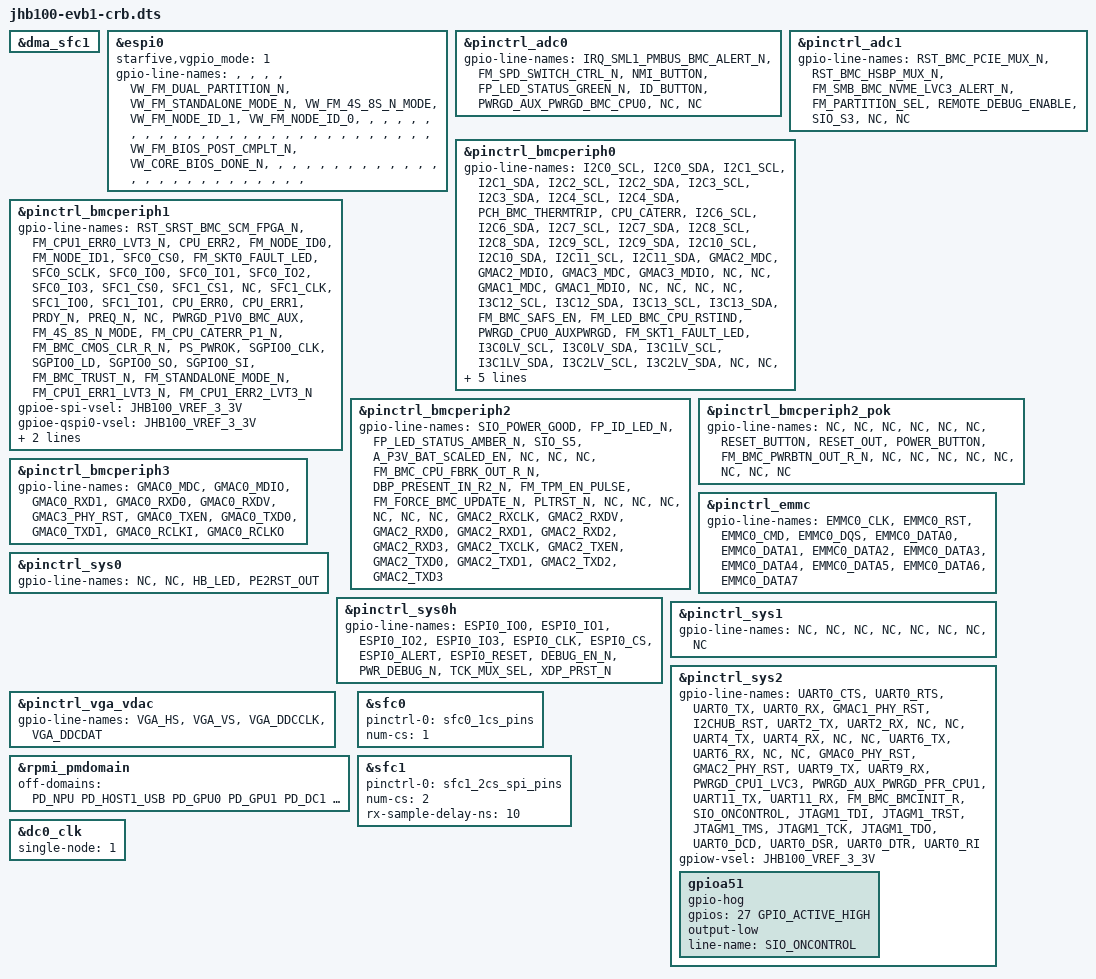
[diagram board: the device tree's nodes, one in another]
// SPDX-License-Identifier: GPL-2.0 OR MIT
/*
 * Copyright (c) 2025 StarFive Technology Co., Ltd.
 */

#include "jhb100-evb1.dtsi"
#include "jhb100-evb1-ethernet.dtsi"
#include "jhb100-evb1-sib1.dtsi"
#include "jhb100-evb1-sfc0-flash.dtsi"
#include "jhb100-evb1-sfc1-flash.dtsi"

&dma_sfc1 {
	status = "okay";
};

&espi0 {
	starfive,vgpio_mode = <1>;
	gpio-line-names  =
										/* Output pins */
		"", "", "", "",							/* VGPIO0-3 */
		"VW_FM_DUAL_PARTITION_N", "VW_FM_STANDALONE_MODE_N",		/* VGPIO4-5 */
		"VW_FM_4S_8S_N_MODE", "VW_FM_NODE_ID_1",			/* VGPIO6-7 */
		"VW_FM_NODE_ID_0", "", "", "", "", "", "", "",			/* VGPIO8-15*/
		"", "", "", "",	"", "", "", "",					/* VGPIO16-23 */
		"", "", "", "",	"", "", "", "",					/* VGPIO23-31 */
										/* Input pins */
		"", "", "", "",							/* VGPIO32-35 */
		"VW_FM_BIOS_POST_CMPLT_N", "VW_CORE_BIOS_DONE_N", "", "",	/* VGPIO36-39 */
		"", "", "", "",	"", "", "", "",					/* VGPIO40-47 */
		"", "", "", "",	"", "", "", "",					/* VGPIO48-55 */
		"", "", "", "",	"", "", "", "";					/* VGPIO56-63 */
};

&pinctrl_adc0 {
	gpio-line-names =
		"IRQ_SML1_PMBUS_BMC_ALERT_N", "FM_SPD_SWITCH_CTRL_N",		/* GPIOG0-1 */
		"NMI_BUTTON", "FP_LED_STATUS_GREEN_N",				/* GPIOG2-3 */
		"ID_BUTTON", "PWRGD_AUX_PWRGD_BMC_CPU0",			/* GPIOG4-5 */
		"NC", "NC";							/* GPIOG6-7 */
};

&pinctrl_adc1 {
	gpio-line-names =
		"RST_BMC_PCIE_MUX_N", "RST_BMC_HSBP_MUX_N",		/* GPIOH0-1 */
		"FM_SMB_BMC_NVME_LVC3_ALERT_N", "FM_PARTITION_SEL",	/* GPIOH2-3 */
		"REMOTE_DEBUG_ENABLE", "SIO_S3", "NC", "NC";		/* GPIOH4-7 */
};

&pinctrl_bmcperiph0 {
	gpio-line-names =
		"I2C0_SCL", "I2C0_SDA", "I2C1_SCL", "I2C1_SDA",			/* GPIOB0-3 */
		"I2C2_SCL", "I2C2_SDA", "I2C3_SCL", "I2C3_SDA",			/* GPIOB4-7 */
		"I2C4_SCL", "I2C4_SDA",						/* GPIOB8-9 */
		"PCH_BMC_THERMTRIP", "CPU_CATERR",				/* GPIOB10-11 */
		"I2C6_SCL", "I2C6_SDA", "I2C7_SCL", "I2C7_SDA",			/* GPIOB12-15 */
		"I2C8_SCL", "I2C8_SDA", "I2C9_SCL", "I2C9_SDA",			/* GPIOB16-19 */
		"I2C10_SCL", "I2C10_SDA", "I2C11_SCL", "I2C11_SDA",		/* GPIOB20-23 */
		"GMAC2_MDC", "GMAC2_MDIO", "GMAC3_MDC", "GMAC3_MDIO",		/* GPIOB24-27 */
		"NC", "NC", "GMAC1_MDC", "GMAC1_MDIO",				/* GPIOB28-31 */
		"NC", "NC", "NC", "NC",						/* GPIOB32-35 */
		"I3C12_SCL", "I3C12_SDA", "I3C13_SCL", "I3C13_SDA",		/* GPIOB36-39 */
		"FM_BMC_SAFS_EN", "FM_LED_BMC_CPU_RSTIND",			/* GPIOB40-41 */
		"PWRGD_CPU0_AUXPWRGD", "FM_SKT1_FAULT_LED",			/* GPIOB42-43 */
		"I3C0LV_SCL", "I3C0LV_SDA", "I3C1LV_SCL", "I3C1LV_SDA",		/* GPIOB44-47 */
		"I3C2LV_SCL", "I3C2LV_SDA", "NC", "NC",				/* GPIOB48-51 */
		"NC", "NC", "NC", "NC",						/* GPIOB52-55 */
		"NC", "NC", "NC", "NC";						/* GPIOB56-59 */

	gpioe-i3c0-vsel = <JHB100_VREF_3_3V>; /* VREF for GPIOB8-11, 32-33 */
	gpioe-i3c1-vsel = <JHB100_VREF_3_3V>; /* VREF for GPIOB12-15, 34-35 */
	gpioe-i3c2-vsel = <JHB100_VREF_3_3V>; /* VREF for GPIOB16-23 */
	gpioe-i3c4-vsel = <JHB100_VREF_3_3V>; /* VREF for GPIOB36-43 */
};

&pinctrl_bmcperiph1 {
	gpio-line-names =
		"RST_SRST_BMC_SCM_FPGA_N", "FM_CPU1_ERR0_LVT3_N",		/* GPIOC0-1 */
		"CPU_ERR2", "FM_NODE_ID0", "FM_NODE_ID1", "SFC0_CS0",		/* GPIOC2-5 */
		"FM_SKT0_FAULT_LED", "SFC0_SCLK",				/* GPIOC6-7 */
		"SFC0_IO0", "SFC0_IO1", "SFC0_IO2", "SFC0_IO3",			/* GPIOC8-11 */
		"SFC1_CS0", "SFC1_CS1", "NC", "SFC1_CLK",			/* GPIOC12-15 */
		"SFC1_IO0", "SFC1_IO1", "CPU_ERR0", "CPU_ERR1",			/* GPIOC16-19 */
		"PRDY_N", "PREQ_N", "NC", "PWRGD_P1V0_BMC_AUX",			/* GPIOC20-23 */
		"FM_4S_8S_N_MODE", "FM_CPU_CATERR_P1_N",			/* GPIOC24-25 */
		"FM_BMC_CMOS_CLR_R_N", "PS_PWROK",				/* GPIOC26-27 */
		"SGPIO0_CLK", "SGPIO0_LD", "SGPIO0_SO", "SGPIO0_SI",		/* GPIOC28-31 */
		"FM_BMC_TRUST_N", "FM_STANDALONE_MODE_N",			/* GPIOC32-33 */
		"FM_CPU1_ERR1_LVT3_N", "FM_CPU1_ERR2_LVT3_N";			/* GPIOC34-35 */

	gpioe-spi-vsel = <JHB100_VREF_3_3V>; /* VREF for GPIOC0-4 */
	gpioe-qspi0-vsel = <JHB100_VREF_3_3V>; /* VREF for GPIOC5-11 */
	gpioe-qspi1-vsel = <JHB100_VREF_3_3V>; /* VREF for GPIOC12-19 */
	gpioe-qspi2-vsel = <JHB100_VREF_3_3V>; /* VREF for GPIOC20-27 */
};

&pinctrl_bmcperiph2 {
	gpio-line-names =
		"SIO_POWER_GOOD", "FP_ID_LED_N",				/* GPIOD0-1 */
		"FP_LED_STATUS_AMBER_N", "SIO_S5",				/* GPIOD2-3 */
		"A_P3V_BAT_SCALED_EN", "NC", "NC", "NC",			/* GPIOD4-7 */
		"FM_BMC_CPU_FBRK_OUT_R_N", "DBP_PRESENT_IN_R2_N",		/* GPIOD8-9 */
		"FM_TPM_EN_PULSE", "FM_FORCE_BMC_UPDATE_N",			/* GPIOD10-11 */
		"PLTRST_N", "NC", "NC", "NC",					/* GPIOD12-15 */
		"NC", "NC", "NC", "GMAC2_RXCLK",				/* GPIOD16-19 */
		"GMAC2_RXDV", "GMAC2_RXD0", "GMAC2_RXD1", "GMAC2_RXD2",		/* GPIOD20-23 */
		"GMAC2_RXD3", "GMAC2_TXCLK", "GMAC2_TXEN", "GMAC2_TXD0",	/* GPIOD24-27 */
		"GMAC2_TXD1", "GMAC2_TXD2", "GMAC2_TXD3";			/* GPIOD28-30 */
};

&pinctrl_bmcperiph2_pok {
	gpio-line-names =
		"NC", "NC", "NC", "NC",				/* GPIOD31-34 */
		"NC", "NC", "RESET_BUTTON", "RESET_OUT",	/* GPIOD35-38 */
		"POWER_BUTTON", "FM_BMC_PWRBTN_OUT_R_N",	/* GPIOD39-40 */
		"NC", "NC", "NC", "NC",				/* GPIOD41-44 */
		"NC", "NC", "NC", "NC";				/* GPIOD45-48 */
};

&pinctrl_bmcperiph3 {
	gpio-line-names =
		"GMAC0_MDC", "GMAC0_MDIO", "GMAC0_RXD1", "GMAC0_RXD0",		/* GPIOE0-3 */
		"GMAC0_RXDV", "GMAC3_PHY_RST", "GMAC0_TXEN", "GMAC0_TXD0",	/* GPIOE4-7 */
		"GMAC0_TXD1", "GMAC0_RCLKI", "GMAC0_RCLKO";			/* GPIOE8-11 */
};

&pinctrl_emmc {
	gpio-line-names =
		"EMMC0_CLK", "EMMC0_RST", "EMMC0_CMD", "EMMC0_DQS",		/* GPIOF0-3 */
		"EMMC0_DATA0", "EMMC0_DATA1", "EMMC0_DATA2", "EMMC0_DATA3",	/* GPIOF4-7 */
		"EMMC0_DATA4", "EMMC0_DATA5", "EMMC0_DATA6", "EMMC0_DATA7";	/* GPIOF8-11 */
};

&pinctrl_sys0 {
	gpio-line-names =
		"NC", "NC", "HB_LED", "PE2RST_OUT";	/* GPIOA0-3 */
};

&pinctrl_sys0h {
	gpio-line-names =
		"ESPI0_IO0", "ESPI0_IO1", "ESPI0_IO2", "ESPI0_IO3",		/* GPIOA4-7 */
		"ESPI0_CLK", "ESPI0_CS", "ESPI0_ALERT", "ESPI0_RESET",		/* GPIOA8-11 */
		"DEBUG_EN_N", "PWR_DEBUG_N", "TCK_MUX_SEL", "XDP_PRST_N";	/* GPIOA12-15 */
};

&pinctrl_sys1 {
	gpio-line-names =
		"NC", "NC", "NC", "NC",		/* GPIOA16-19 */
		"NC", "NC", "NC", "NC";		/* GPIOA20-23 */
};

&pinctrl_sys2 {
	gpio-line-names =
		"UART0_CTS", "UART0_RTS", "UART0_TX", "UART0_RX",		/* GPIOA24-27 */
		"GMAC1_PHY_RST", "I2CHUB_RST", "UART2_TX", "UART2_RX",		/* GPIOA28-31 */
		"NC", "NC", "UART4_TX", "UART4_RX",				/* GPIOA32-35 */
		"NC", "NC", "UART6_TX", "UART6_RX",				/* GPIOA36-39 */
		"NC", "NC", "GMAC0_PHY_RST", "GMAC2_PHY_RST",			/* GPIOA40-43 */
		"UART9_TX", "UART9_RX",						/* GPIOA44-45 */
		"PWRGD_CPU1_LVC3", "PWRGD_AUX_PWRGD_PFR_CPU1",			/* GPIOA46-47 */
		"UART11_TX", "UART11_RX", "FM_BMC_BMCINIT_R", "SIO_ONCONTROL",	/* GPIOA48-51 */
		"JTAGM1_TDI", "JTAGM1_TRST", "JTAGM1_TMS", "JTAGM1_TCK",	/* GPIOA52-55 */
		"JTAGM1_TDO", "UART0_DCD", "UART0_DSR", "UART0_DTR",		/* GPIOA56-59 */
		"UART0_RI";							/* GPIOA60 */

	gpiow-vsel = <JHB100_VREF_3_3V>; /* VREF for GPIOA36-43 */

	gpioa51 {
		gpio-hog;
		gpios = <27 GPIO_ACTIVE_HIGH>;
		output-low;
		line-name = "SIO_ONCONTROL";
	};
};

&pinctrl_vga_vdac {
	gpio-line-names =
		"VGA_HS", "VGA_VS", "VGA_DDCCLK", "VGA_DDCDAT";		/* GPIOI0-3 */
};

&rpmi_pmdomain {
	off-domains = <PD_NPU PD_HOST1_USB PD_GPU0 PD_GPU1 PD_DC1 PD_HOSTSS_i1>;
};

&sfc0 {
	pinctrl-0 = <&sfc0_1cs_pins>;
	num-cs = <1>;
	/delete-node/ flash@1;
};

&sfc1 {
	pinctrl-0 = <&sfc1_2cs_spi_pins>;
	status = "okay";
	num-cs = <2>;
	rx-sample-delay-ns = <10>;
};

&dc0_clk {
	single-node = <1>;
	status = "okay";
};
